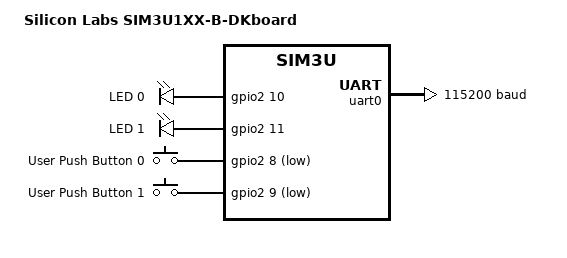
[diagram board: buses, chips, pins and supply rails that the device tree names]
/*
 * Copyright (c) 2019 Christian Taedcke
 *
 * SPDX-License-Identifier: Apache-2.0
 */

/dts-v1/;
#include <silabs/sim3u167bgm.dtsi>

/ {
	model = "Silicon Labs  SIM3U1XX-B-DKboard";
	compatible = "silabs,sim3u1xx_b_dk", "silabs,sim3u";

	chosen {
		zephyr,console = &uart0;
		zephyr,shell-uart = &uart0;
		zephyr,sram = &sram0;
		zephyr,flash = &flash0;
	};

	/* These aliases are provided for compatibility with samples */
	aliases {
		led0 = &led0;
		led1 = &led1;
		sw0 = &button0;
		sw1 = &button1;
	};

	leds {
		compatible = "gpio-leds";
		led0: led_0 {
			gpios = <&gpio2 10 0>;
			label = "LED 0";
		};
		led1: led_1 {
			gpios = <&gpio2 11 0>;
			label = "LED 1";
		};
	};

	buttons {
		compatible = "gpio-keys";
		button0: button_0 {
			/* gpio flags need validation */
			gpios = <&gpio2 8 GPIO_INT_ACTIVE_LOW>;
			label = "User Push Button 0";
		};
		button1: button_1 {
			/* gpio flags need validation */
			gpios = <&gpio2 9 GPIO_INT_ACTIVE_LOW>;
			label = "User Push Button 1";
		};
	};
};

&uart0 {
	current-speed = <115200>;
	status = "ok";
};
